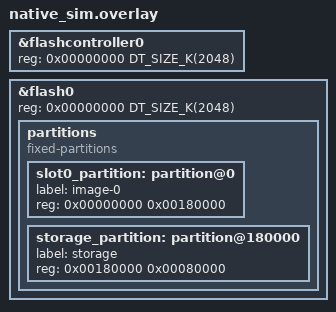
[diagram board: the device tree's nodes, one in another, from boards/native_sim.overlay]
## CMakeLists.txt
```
# SPDX-License-Identifier: GPL-3.0-or-later
#
# Transport + pairing T-03 strict-mode conformance: build session_slot.c with
# CONFIG_CANTIL_SESSION_X509_STRICT=y and confirm that a stored session cert
# whose identity fields no longer match the build constant latches recovery
# mode, while a matching cert does not. The non-strict comparison helper and
# warn-continue path are covered by the session_slot test app.
#
# Build:
#   ZEPHYR_TOOLCHAIN_VARIANT=host \
#     west build -p -b native_sim firmware/tests/session_recovery --no-sysbuild
#   west build -t run

cmake_minimum_required(VERSION 3.20.0)

find_package(Zephyr REQUIRED HINTS $ENV{ZEPHYR_BASE})
project(session_recovery_tests LANGUAGES C)

set(FW ${CMAKE_CURRENT_SOURCE_DIR}/../..)

# Encode the real session X.509 identity constant from the production TOML.
set(SESSION_X509_TOML ${FW}/session_x509.toml)
set(SESSION_X509_GEN ${CMAKE_CURRENT_BINARY_DIR}/cantil_session_x509_constant.c)
add_custom_command(
    OUTPUT ${SESSION_X509_GEN}
    COMMAND ${PYTHON_EXECUTABLE}
            ${FW}/../scripts/encode_session_x509.py
            ${SESSION_X509_TOML}
            --c ${SESSION_X509_GEN}
    DEPENDS ${SESSION_X509_TOML}
            ${FW}/../scripts/encode_session_x509.py
    COMMENT "Encoding session X.509 identity constant for ztest"
    VERBATIM
)

target_sources(app PRIVATE
    src/main.c
    ${SESSION_X509_GEN}
    ${FW}/src/session/session_slot.c
    ${FW}/src/session/noise_crypto_wolfssl.c
    ${FW}/src/ca/ca.c
    ${FW}/src/ca/der_write.c
    ${FW}/src/ca/certparse_wolfssl.c
    ${FW}/src/ca/certgen_wolfssl.c
    ${FW}/src/crypto/crypto_wolfssl.c
    ${FW}/src/crypto/wc_rand.c
    ${FW}/src/crypto/zeroize.c
    ${FW}/src/storage/storage.c
    ${FW}/src/storage/volume_marker.c
    ${FW}/src/crypto/device_id.c
    ${FW}/../common/cbor/cantil_cbor.c
)

target_include_directories(app PRIVATE
    ${FW}/src
    ${FW}/include
    ${FW}/../common/cbor
)

# cantil_wolfssl_user_settings.h lives here.
zephyr_include_directories(${FW}/include)

# Carries WOLFSSL_USER_SETTINGS / WOLFSSL_ZEPHYR defines.
target_link_libraries(app PRIVATE wolfSSL)
```

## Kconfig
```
# SPDX-License-Identifier: GPL-3.0-or-later

mainmenu "session_recovery ztest"

# Mirror of firmware/Kconfig:CANTIL_MAX_KEY_SLOTS — defined locally so this
# test app can be built standalone against Kconfig.zephyr without pulling in
# the full firmware Kconfig tree (USB/BLE/IMU etc). Keep in sync with the
# production definition; ca.c / storage.c key off it via CONFIG_*.
config CANTIL_MAX_KEY_SLOTS
	int "Maximum number of key slots"
	default 8
	range 1 64

config CANTIL_CRL_VALIDITY_SEC
	int "CRL nextUpdate window (seconds)"
	default 86400

# This test app exercises the T-03 *strict* recovery path, so force it on here
# (the production default lives in firmware/Kconfig + the release .conf).
config CANTIL_SESSION_X509_STRICT
	bool
	default y

source "Kconfig.zephyr"
```

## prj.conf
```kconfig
# ztest framework
CONFIG_ZTEST=y

# Slot count must match the production default.
CONFIG_CANTIL_MAX_KEY_SLOTS=8

# Entropy — native_sim has zephyr,native-posix-rng.
CONFIG_ENTROPY_GENERATOR=y
CONFIG_TEST_RANDOM_GENERATOR=y

# Device-id source for the FICR-derived CN (falls back to "Cantil" if absent).
CONFIG_HWINFO=y

# plus the Noise primitives session_slot.c pulls via noise_crypto_wolfssl.c
# (X25519 keygen / ChaCha20-Poly1305 / SHA-256).

# X.509 writer + parser (needed to emit and re-parse cert.der).

# LittleFS on the sim flash partition (storage_partition enlarged by overlay).
CONFIG_FLASH=y
CONFIG_FLASH_MAP=y
CONFIG_FILE_SYSTEM=y
CONFIG_FILE_SYSTEM_LITTLEFS=y
CONFIG_FS_LITTLEFS_FMP_DEV=y
CONFIG_FILE_SYSTEM_MKFS=y

CONFIG_MAIN_STACK_SIZE=16384
CONFIG_HEAP_MEM_POOL_SIZE=32768

# crc32_ieee — storage.c volume identity marker
CONFIG_CRC=y

# wolfCrypt — primitives selected by the settings header, not Kconfig.
CONFIG_WOLFSSL=y
CONFIG_WOLFSSL_BUILTIN=y
CONFIG_WOLFSSL_SETTINGS_FILE="cantil_wolfssl_user_settings.h"
```

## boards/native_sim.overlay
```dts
/*
 * Enlarge the sim flash + give storage_partition enough room for LittleFS.
 * Default native_sim layout puts storage_partition at 16 KB which is too
 * small to comfortably hold the slot 0 bootstrap blobs (key+meta+x509+cert).
 *
 * No bootloader partition is needed here, so the layout is just: code at the bottom,
 * 512 KB of storage at the top.
 */

&flashcontroller0 {
	reg = <0x00000000 DT_SIZE_K(2048)>;
};

&flash0 {
	reg = <0x00000000 DT_SIZE_K(2048)>;
	partitions {
		compatible = "fixed-partitions";
		#address-cells = <1>;
		#size-cells = <1>;

		/delete-node/ partition@0;
		/delete-node/ partition@c000;
		/delete-node/ partition@75000;
		/delete-node/ partition@de000;
		/delete-node/ partition@fc000;

		slot0_partition: partition@0 {
			label = "image-0";
			reg = <0x00000000 0x00180000>;
		};
		storage_partition: partition@180000 {
			label = "storage";
			reg = <0x00180000 0x00080000>;
		};
	};
};
```

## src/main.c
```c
/* SPDX-License-Identifier: GPL-3.0-or-later */
/* See LICENSE at the repo root. */

/*
 * Strict-mode session-identity recovery (transport + pairing T-03).
 *
 * Built with CONFIG_CANTIL_SESSION_X509_STRICT=y (forced in this app's local
 * Kconfig). Confirms that session_slot_init():
 *   - does NOT enter recovery when the stored cert matches the build constant;
 *   - DOES latch recovery mode when a planted cert's identity fields differ.
 *
 * Because the recovery flag latches for the lifetime of the binary, both
 * assertions live in a single test so ordering is deterministic regardless of
 * how ztest schedules suites.
 */

#include <zephyr/kernel.h>
#include <zephyr/ztest.h>
#include <zephyr/fs/fs.h>
#include <string.h>
#include <errno.h>

#include "session/session_slot.h"
#include "session/session_x509.h"
#include "ca/ca.h"
#include "crypto/crypto.h"
#include "storage/storage.h"

#define LFS_MOUNT    "/lfs"
#define SESSION_DIR  LFS_MOUNT "/session"
#define SESSION_CERT SESSION_DIR "/cert.der"
#define NOISE_DIR    LFS_MOUNT "/noise"

static void wipe_dir(const char *dir)
{
	struct fs_dir_t d;
	struct fs_dirent ent;
	char path[128];

	fs_dir_t_init(&d);
	if (fs_opendir(&d, dir) != 0) {
		return;
	}
	while (fs_readdir(&d, &ent) == 0 && ent.name[0] != '\0') {
		snprintf(path, sizeof(path), "%s/%s", dir, ent.name);
		fs_unlink(path);
	}
	fs_closedir(&d);
	fs_unlink(dir);
}

/* First O-value byte offset: 6-byte header, [cn_len][cn], [o_len], O… */
static size_t blob_o_value_off(const uint8_t *blob)
{
	size_t off = 6;
	uint8_t cn_len = blob[off];

	off += 1 + cn_len + 1;
	return off;
}

static void *suite_setup(void)
{
	zassert_ok(storage_init(), "storage_init failed");

	/*
	 * A fresh native_sim volume has no identity marker, and minting is now
	 * refused on an unmarked, empty volume — that combination is what a
	 * misdeclared partition looks like. Mark it, which is exactly what the
	 * factory image does to real hardware before anything is provisioned.
	 */
	(void)storage_volume_marker_write();
	wipe_dir(SESSION_DIR);
	wipe_dir(NOISE_DIR);
	return NULL;
}

ZTEST_SUITE(session_recovery, NULL, suite_setup, NULL, NULL, NULL);

ZTEST(session_recovery, test_strict_recovery_on_mismatch)
{
	/* Sanity: STRICT must actually be compiled in for this app. */
	zassert_true(IS_ENABLED(CONFIG_CANTIL_SESSION_X509_STRICT),
		     "this app must build with STRICT=y");

	/* 1. First boot writes the real (matching) identity. Re-init verifies it
	 *    and must NOT enter recovery. */
	zassert_ok(session_slot_init(), "first-boot init");
	zassert_ok(session_slot_init(), "verify-path init (matching)");
	zassert_false(session_slot_in_recovery(), "matching identity must not trip recovery");

	/* 2. Overwrite cert.der with a cert whose O differs from the constant. */
	uint8_t blob[256];

	zassert_true(cantil_session_x509_constant_len <= sizeof(blob), "blob fits");
	memcpy(blob, cantil_session_x509_constant, cantil_session_x509_constant_len);
	blob[blob_o_value_off(blob)] ^= 0x20; /* perturb O */

	uint8_t id_priv[64];
	size_t id_len = sizeof(id_priv);

	zassert_ok(crypto_keygen(id_priv, &id_len), "P-256 keygen");
	zassert_equal(id_len, 32, "P-256 scalar is 32 bytes");

	uint8_t x25519_pub[32] = {0};
	uint8_t cert[2048];
	size_t cert_len = sizeof(cert);

	zassert_ok(ca_build_session_cert(blob, cantil_session_x509_constant_len, "Cantil", id_priv,
					 x25519_pub, cert, &cert_len),
		   "build mismatching cert");
	zassert_ok(storage_session_cert_write(cert, cert_len), "plant cert.der");

	/* 3. The verify path now sees a mismatch and, under strict mode, latches
	 *    recovery. Boot still returns OK so the device stays responsive to
	 *    DEVICE_STATUS / RESET_DEVICE. */
	zassert_ok(session_slot_init(), "init returns OK (recovery, not error)");
	zassert_true(session_slot_in_recovery(), "strict mismatch must latch recovery mode");
}
```
